# CY8C5868AXI_LP035 register map
File version: 0.1
CY8C58LP
Registers are 8-bit, read-write, no defined reset value unless marked. A register's access mark holds for its fields unless they carry their own. Offsets are from the block's base; lines under a group give offsets from that group; [hi:lo] are bit positions; {n}, {i} and the like mark numbered series; 'fields as' and 'values as' point back to an identical list; <NAME> marks a mode.

## Memory map
0x00000000 UART_Debug — UART
0x00000000 UART_Linux — UART

## UART_Debug — UART
Base 0x00000000
0x40006447 TX_UART_Debug_TX_DATA — TX Data Register
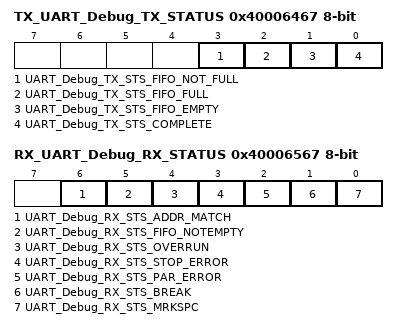
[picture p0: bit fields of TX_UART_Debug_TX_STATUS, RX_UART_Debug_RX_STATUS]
0x40006467 TX_UART_Debug_TX_STATUS — TX status register
  [3] UART_Debug_TX_STS_FIFO_NOT_FULL ro, [2] UART_Debug_TX_STS_FIFO_FULL ro, [1] UART_Debug_TX_STS_FIFO_EMPTY ro, [0] UART_Debug_TX_STS_COMPLETE ro
0x40006524 RX_UART_Debug_RX_ADDRESS1 — RX Address1 Register
0x40006534 RX_UART_Debug_RX_ADDRESS2 — RX Address2 Register
0x40006544 RX_UART_Debug_RX_DATA — RX Data Register
0x40006567 RX_UART_Debug_RX_STATUS — RX status register
  [6] UART_Debug_RX_STS_ADDR_MATCH ro, [5] UART_Debug_RX_STS_FIFO_NOTEMPTY ro, [4] UART_Debug_RX_STS_OVERRUN ro, [3] UART_Debug_RX_STS_STOP_ERROR ro, [2] UART_Debug_RX_STS_PAR_ERROR ro, [1] UART_Debug_RX_STS_BREAK ro, [0] UART_Debug_RX_STS_MRKSPC ro

## UART_Linux — UART
Base 0x00000000
0x40006425 RX_UART_Linux_RX_ADDRESS1 — RX Address1 Register
0x40006435 RX_UART_Linux_RX_ADDRESS2 — RX Address2 Register
0x40006445 RX_UART_Linux_RX_DATA — RX Data Register
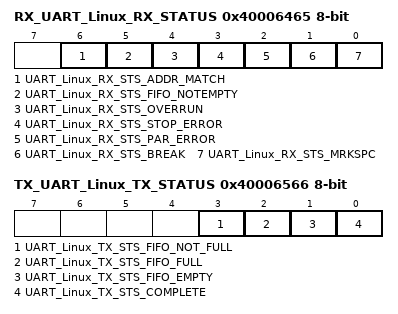
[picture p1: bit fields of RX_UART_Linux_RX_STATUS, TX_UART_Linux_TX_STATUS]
0x40006465 RX_UART_Linux_RX_STATUS — RX status register
  [6] UART_Linux_RX_STS_ADDR_MATCH ro, [5] UART_Linux_RX_STS_FIFO_NOTEMPTY ro, [4] UART_Linux_RX_STS_OVERRUN ro, [3] UART_Linux_RX_STS_STOP_ERROR ro, [2] UART_Linux_RX_STS_PAR_ERROR ro, [1] UART_Linux_RX_STS_BREAK ro, [0] UART_Linux_RX_STS_MRKSPC ro
0x40006546 TX_UART_Linux_TX_DATA — TX Data Register
0x40006566 TX_UART_Linux_TX_STATUS — TX status register
  [3] UART_Linux_TX_STS_FIFO_NOT_FULL ro, [2] UART_Linux_TX_STS_FIFO_FULL ro, [1] UART_Linux_TX_STS_FIFO_EMPTY ro, [0] UART_Linux_TX_STS_COMPLETE ro
